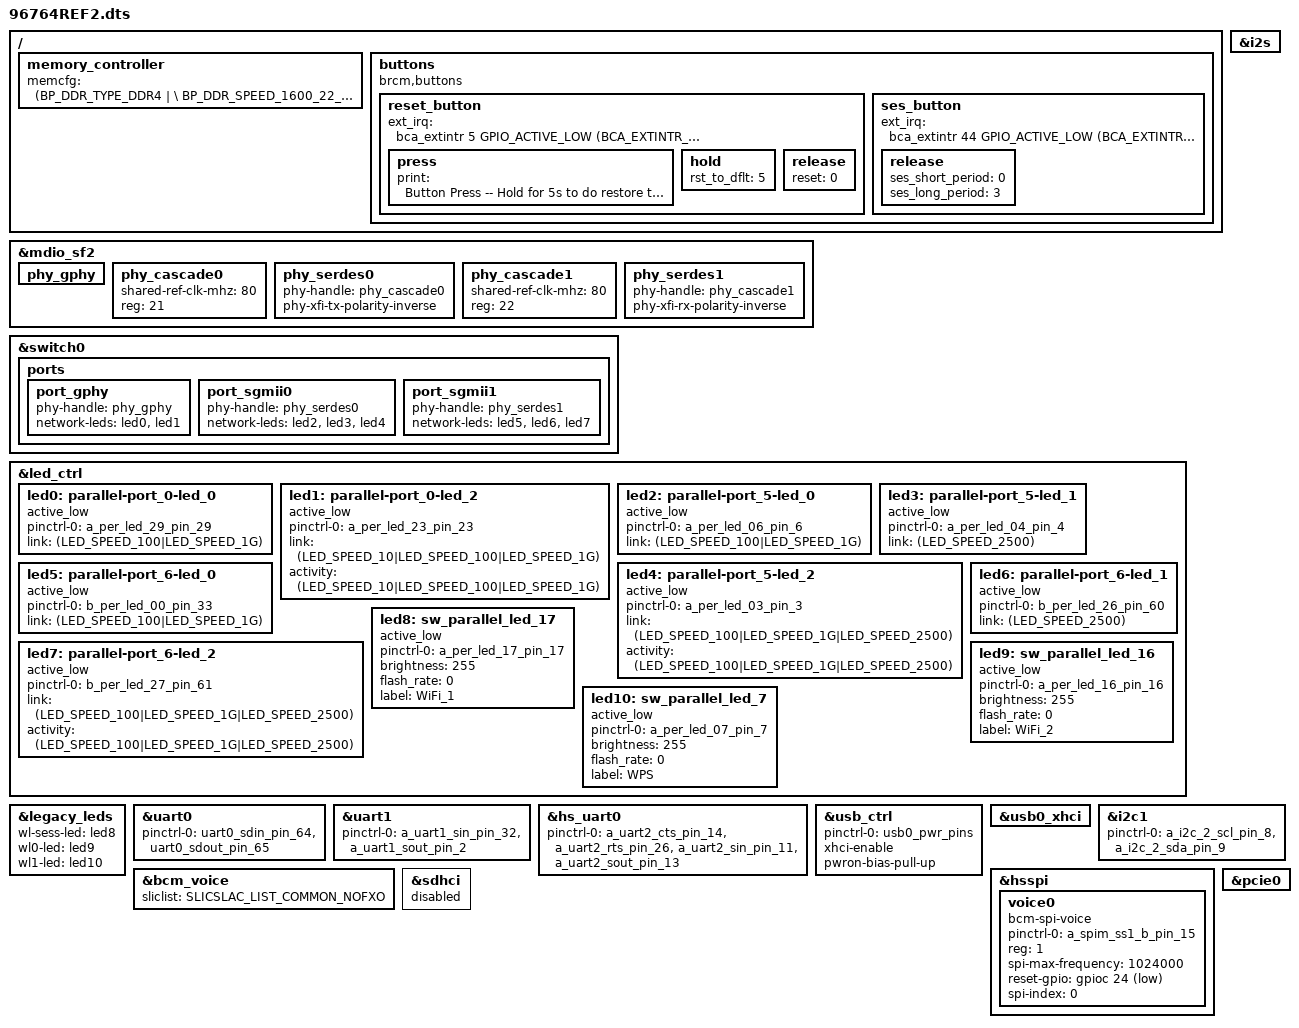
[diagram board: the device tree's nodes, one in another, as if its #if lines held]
#include "6764.dtsi"
#include "../bcm_voice.dtsi"

/ {

	memory_controller {
		memcfg = <(BP_DDR_TYPE_DDR4       | \
			BP_DDR_SPEED_1600_22_22_22    | \
			BP_DDR_TOTAL_SIZE_2048MB      | \
			BP_DDR_DEVICE_WIDTH_16         | \
			BP_DDR_TOTAL_WIDTH_16BIT      | \
			BP_DDR_6764_DEFAULT           | \
			BP_DDR_CONFIG_DEBUG)>;
	};
	buttons {
		compatible = "brcm,buttons";
		reset_button {
			ext_irq = <&bca_extintr 5 GPIO_ACTIVE_LOW (BCA_EXTINTR_TYPE_LOW_LEVEL | BCA_EXTINTR_TYPE_SENSE_EDGE)>;
			press {
				print = "Button Press -- Hold for 5s to do restore to default";
			};
			hold {
				rst_to_dflt = <5>;
			};
			release {
				reset = <0>;
			};
		};
		ses_button {
			ext_irq = <&bca_extintr 44 GPIO_ACTIVE_LOW (BCA_EXTINTR_TYPE_LOW_LEVEL | BCA_EXTINTR_TYPE_SENSE_EDGE)>;
			release {
				ses_short_period = <0>;
				ses_long_period = <3>;
			};
		};
	};
};
&mdio_sf2 {
	/* Port PHY mapping:
	        port_imp -8#0- port_gphy <----> phy_gphy
	                  # 5- port_sgmii0 <--> phy_serdes0 - phy_cascade0
	                  ##6- port_sgmii1 <--> phy_serdes1 - phy_cascade1
	 */
	phy_gphy {
		status = "okay";
	};
	phy_cascade0 {
		shared-ref-clk-mhz = <80>;
		reg = <21>;
		status = "okay";
	};
	phy_serdes0 {
		phy-handle = <&phy_cascade0>;
		phy-xfi-tx-polarity-inverse;
		status = "okay";
	};
	phy_cascade1 {
		shared-ref-clk-mhz = <80>;
		reg = <22>;
		status = "okay";
	};
	phy_serdes1 {
		phy-handle = <&phy_cascade1>;
		phy-xfi-rx-polarity-inverse;
		status = "okay";
	};
};

&switch0 {

	ports {
		port_gphy {
			phy-handle = <&phy_gphy>;
			network-leds = <&led0 &led1>;
			status = "okay";
		};
		port_sgmii0 {
			phy-handle = <&phy_serdes0>;
			network-leds = <&led2 &led3 &led4>;
			status = "okay";
		};
		port_sgmii1 {
			phy-handle = <&phy_serdes1>;
			network-leds = <&led5 &led6 &led7>;
			status = "okay";
		};
	};
};

&led_ctrl {

	led0:parallel-port_0-led_0 {
		active_low;
		pinctrl-0 = <&a_per_led_29_pin_29>;
		link = <(LED_SPEED_100|LED_SPEED_1G)>;
		status="okay";
	};
	led1:parallel-port_0-led_2 {
		active_low;
		pinctrl-0 = <&a_per_led_23_pin_23>;
		link = <(LED_SPEED_10|LED_SPEED_100|LED_SPEED_1G)>;
		activity = <(LED_SPEED_10|LED_SPEED_100|LED_SPEED_1G)>;
		status="okay";
	};
	led2:parallel-port_5-led_0 {
		active_low;
		pinctrl-0 = <&a_per_led_06_pin_6>;
		link = <(LED_SPEED_100|LED_SPEED_1G)>;
		status="okay";
	};
	led3:parallel-port_5-led_1 {
		active_low;
		pinctrl-0 = <&a_per_led_04_pin_4>;
		link = <(LED_SPEED_2500)>;
		status="okay";
	};
	led4:parallel-port_5-led_2 {
		active_low;
		pinctrl-0 = <&a_per_led_03_pin_3>;
		link = <(LED_SPEED_100|LED_SPEED_1G|LED_SPEED_2500)>;
		activity = <(LED_SPEED_100|LED_SPEED_1G|LED_SPEED_2500)>;
		status="okay";
	};

	led5:parallel-port_6-led_0 {
		active_low;
		pinctrl-0 = <&b_per_led_00_pin_33>;
		link = <(LED_SPEED_100|LED_SPEED_1G)>;
		status="okay";
	};
	led6:parallel-port_6-led_1 {
		active_low;
		pinctrl-0 = <&b_per_led_26_pin_60>;
		link = <(LED_SPEED_2500)>;
		status="okay";
	};
	led7:parallel-port_6-led_2 {
		active_low;
		pinctrl-0 = <&b_per_led_27_pin_61>;
		link = <(LED_SPEED_100|LED_SPEED_1G|LED_SPEED_2500)>;
		activity = <(LED_SPEED_100|LED_SPEED_1G|LED_SPEED_2500)>;
		status="okay";
	};

	led8: sw_parallel_led_17 {
		active_low;
		pinctrl-0 = <&a_per_led_17_pin_17>;
		brightness = <255>;
		flash_rate = <0>;
		status = "okay";
		label = "WiFi_1";
	};

	led9: sw_parallel_led_16 {
		active_low;
		pinctrl-0 = <&a_per_led_16_pin_16>;
		brightness = <255>;
		flash_rate = <0>;
		status = "okay";
		label = "WiFi_2";
	};
	led10: sw_parallel_led_7 {
		active_low;
		pinctrl-0 = <&a_per_led_07_pin_7>;
		brightness = <255>;
		flash_rate = <0>;
		status = "okay";
		label = "WPS";
	};

};

&legacy_leds {
	wl-sess-led = <&led8>;
	wl0-led = <&led9>;
	wl1-led = <&led10>;
};

&uart0 {
	pinctrl-names = "default";
	pinctrl-0 = <&uart0_sdin_pin_64 &uart0_sdout_pin_65>;
	status = "okay";
};

&uart1 {
    pinctrl-names = "default";
    pinctrl-0 = <&a_uart1_sin_pin_32 &a_uart1_sout_pin_2>;
    status = "okay";
};
&hs_uart0 {
	pinctrl-0 = <&a_uart2_cts_pin_14 &a_uart2_rts_pin_26 &a_uart2_sin_pin_11 &a_uart2_sout_pin_13>;
	pinctrl-names = "default";
	status = "okay";
};
&usb_ctrl {
	pinctrl-names="default";
	pinctrl-0 = <&usb0_pwr_pins>;
	status = "okay";
	xhci-enable;
	pwron-bias-pull-up;
};

&usb0_xhci {
	status = "okay";
};

&i2s {
	status = "okay";
};

&i2c1 {

	pinctrl-names="default";
	pinctrl-0 = <&a_i2c_2_scl_pin_8 &a_i2c_2_sda_pin_9>;
	status = "okay";
};

&bcm_voice{
	sliclist = SLICSLAC_LIST_COMMON_NOFXO;
 };

&hsspi {
	status = "okay";
	voice0 {
		pinctrl-0 = <&a_spim_ss1_b_pin_15>;
		pinctrl-names = "default";
		compatible = "bcm-spi-voice";
		reg = <1>; /* chip select 1 */
		spi-max-frequency = <1024000>;
		reset-gpio = <&gpioc 24 GPIO_ACTIVE_LOW>;
		spi-index = <0>;/* voice header index */
	};
};

&sdhci {
	status = "disabled";
};

#if defined(CONFIG_BCM_PCIE_HCD) || defined(CONFIG_BCM_PCIE_HCD_MODULE)
/**********************************************************************/
/* GPIO: Add one define per GPIO (individual or shared) regulator     */
/*       - Skip if no GPIO regulators in use                          */
/**********************************************************************/
#define PCIE0_REG_GPIO    30    /* PCIE_PWR_CTRL for vreg_pcie0 node */

#include "../bcm_wlan_regulator.dtsi"

/**********************************************************************/
/* Shared: Add brcm,supply-names = "vreg-pcieX" for shared PCIe nodes */
/*         - Skip if not using shared GPIO regulators                 */
/**********************************************************************/

/**********************************************************************/
/* PCIe: Add status = "okay" for each PCIe slots of this boiard       */
/*       - Skip if this is a derivative board (already done in base)  */
/**********************************************************************/
&pcie0 {
	status = "okay";
};
#endif //#if defined(CONFIG_BCM_PCIE_HCD) || defined(CONFIG_BCM_PCIE_HCD_MODULE)
